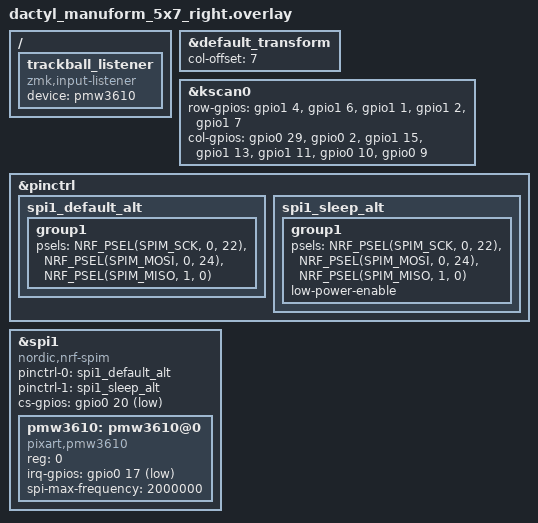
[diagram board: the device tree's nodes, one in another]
#include "dactyl_manuform_5x7.dtsi"
#include <zephyr/dt-bindings/input/input-event-codes.h>

&default_transform {
    col-offset = <7>;
};

&kscan0 {
    row-gpios
        = <&gpio1  4 (GPIO_ACTIVE_HIGH | GPIO_PULL_DOWN)>,
          <&gpio1  6 (GPIO_ACTIVE_HIGH | GPIO_PULL_DOWN)>,
          <&gpio1  1 (GPIO_ACTIVE_HIGH | GPIO_PULL_DOWN)>,
          <&gpio1  2 (GPIO_ACTIVE_HIGH | GPIO_PULL_DOWN)>,
          <&gpio1  7 (GPIO_ACTIVE_HIGH | GPIO_PULL_DOWN)>;

    col-gpios
        = <&gpio0 29 GPIO_ACTIVE_HIGH>,
          <&gpio0  2 GPIO_ACTIVE_HIGH>,
          <&gpio1 15 GPIO_ACTIVE_HIGH>,
          <&gpio1 13 GPIO_ACTIVE_HIGH>,
          <&gpio1 11 GPIO_ACTIVE_HIGH>,
          <&gpio0 10 GPIO_ACTIVE_HIGH>,
          <&gpio0  9 GPIO_ACTIVE_HIGH>;
};

&pinctrl {
    spi1_default_alt: spi1_default_alt {
        group1 {
            psels = <NRF_PSEL(SPIM_SCK, 0, 22)>,
                    <NRF_PSEL(SPIM_MOSI, 0, 24)>,
                    <NRF_PSEL(SPIM_MISO, 1, 0)>;
        };
    };

    spi1_sleep_alt: spi1_sleep_alt {
        group1 {
            psels = <NRF_PSEL(SPIM_SCK, 0, 22)>,
                    <NRF_PSEL(SPIM_MOSI, 0, 24)>,
                    <NRF_PSEL(SPIM_MISO, 1, 0)>;
            low-power-enable;
        };
    };
};

&spi1 {
    status = "okay";
    compatible = "nordic,nrf-spim";
    pinctrl-0 = <&spi1_default_alt>;
    pinctrl-1 = <&spi1_sleep_alt>;
    pinctrl-names = "default", "sleep";
    cs-gpios = <&gpio0 20 GPIO_ACTIVE_LOW>;

    pmw3610: pmw3610@0 {
        compatible = "pixart,pmw3610";
        reg = <0>;
        irq-gpios = <&gpio0 17 (GPIO_ACTIVE_LOW | GPIO_PULL_UP)>;
        spi-max-frequency = <2000000>;
    };
};

/ {
  trackball_listener {
    compatible = "zmk,input-listener";
    device = <&pmw3610>;
  };
};
